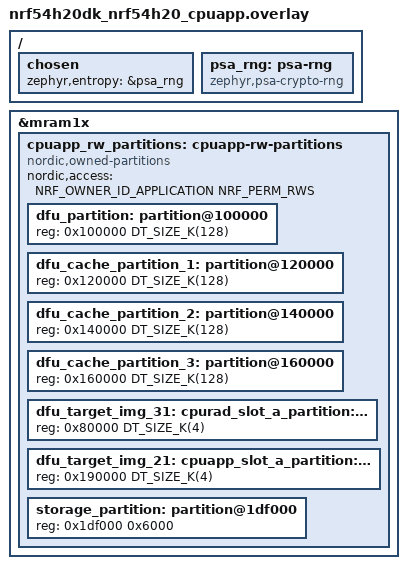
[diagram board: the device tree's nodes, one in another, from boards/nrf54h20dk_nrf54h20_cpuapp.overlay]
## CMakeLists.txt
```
#
# Copyright (c) 2024 Nordic Semiconductor
#
# SPDX-License-Identifier: LicenseRef-Nordic-5-Clause
#

cmake_minimum_required(VERSION 3.20.0)

find_package(Zephyr REQUIRED HINTS $ENV{ZEPHYR_BASE})
project(dfu_target_suit_test)
include(${ZEPHYR_NRF_MODULE_DIR}/tests/subsys/suit/cmake/test_template.cmake)

FILE(GLOB app_sources src/*.c)
target_sources(app PRIVATE ${app_sources})

target_include_directories(app
  PRIVATE
  ${ZEPHYR_NRF_MODULE_DIR}/subsys/dfu/include
  ${ZEPHYR_NRF_MODULE_DIR}/subsys/suit/ipuc/include
  ${ZEPHYR_NRF_MODULE_DIR}/subsys/suit/memory_layout/include
  "src"
  )

zephyr_compile_definitions(CONFIG_SOC_NRF54H20_CPUAPP)
```

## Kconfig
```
#
# Copyright (c) 2024 Nordic Semiconductor ASA
#
# SPDX-License-Identifier: LicenseRef-Nordic-5-Clause
#

menuconfig TESTS_SUIT_DFU_TARGET_SUIT_CACHE_PROCESSING
	bool "Run tests for processing of SUIT cache partition by the SUIT DFU target"
	imply DFU_TARGET_SUIT_CACHE_PROCESSING

menuconfig TESTS_SUIT_DFU_TARGET_SUIT_SINGLE_PARTITION
	bool "Run tests for processing of the dfu_partition only by the DFU target"

menuconfig TESTS_SUIT_DFU_TARGET_SUIT_CACHE_IPUC_PROCESSING
	bool "Run tests for processing of SUIT cache IPUC-based partition by the SUIT DFU target"
	imply DFU_TARGET_SUIT_CACHE_PROCESSING

config SUIT_CACHE_SDFW_IPUC_ID
	default 10
	depends on TESTS_SUIT_DFU_TARGET_SUIT_CACHE_IPUC_PROCESSING

source "Kconfig.zephyr"
```

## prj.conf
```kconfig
#
# Copyright (c) 2024 Nordic Semiconductor ASA
#
# SPDX-License-Identifier: LicenseRef-Nordic-5-Clause
#
CONFIG_ZTEST=y

# Enable suit
CONFIG_SUIT=y
CONFIG_SUIT_DFU=y

# Enable dfu_target
CONFIG_DFU_TARGET=y
CONFIG_DFU_TARGET_SUIT=y

# Initialize SUIT DFU by dfu_target since it is the only
# one SUIT DFU implementation in use
CONFIG_DFU_TARGET_SUIT_INITIALIZE_SUIT=y

# Choose SUIT platform APP
CONFIG_SUIT_PLATFORM_VARIANT_APP=y
```

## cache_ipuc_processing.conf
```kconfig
#
# Copyright (c) 2025 Nordic Semiconductor ASA
#
# SPDX-License-Identifier: LicenseRef-Nordic-5-Clause
#

CONFIG_TESTS_SUIT_DFU_TARGET_SUIT_CACHE_IPUC_PROCESSING=y
CONFIG_SUIT_DFU_CANDIDATE_PROCESSING_PUSH_TO_CACHE=y

CONFIG_FLASH_IPUC=y
CONFIG_FLASH_IPUC_COUNT=5
CONFIG_SUIT_IPUC=y
CONFIG_SUIT_CACHE_SDFW_IPUC=y
CONFIG_SUIT_CACHE_APP_IPUC=y
```

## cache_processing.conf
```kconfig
#
# Copyright (c) 2024 Nordic Semiconductor ASA
#
# SPDX-License-Identifier: LicenseRef-Nordic-5-Clause
#

CONFIG_TESTS_SUIT_DFU_TARGET_SUIT_CACHE_PROCESSING=y
CONFIG_SUIT_DFU_CANDIDATE_PROCESSING_PUSH_TO_CACHE=y
```

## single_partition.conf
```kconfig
#
# Copyright (c) 2024 Nordic Semiconductor ASA
#
# SPDX-License-Identifier: LicenseRef-Nordic-5-Clause
#

CONFIG_TESTS_SUIT_DFU_TARGET_SUIT_SINGLE_PARTITION=y
CONFIG_SUIT_DFU_CANDIDATE_PROCESSING_MINIMAL=y
```

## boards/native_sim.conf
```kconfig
#
# Copyright (c) 2024 Nordic Semiconductor ASA
#
# SPDX-License-Identifier: LicenseRef-Nordic-5-Clause
#

CONFIG_ZCBOR=y
CONFIG_ZCBOR_CANONICAL=y
CONFIG_FLASH_SIMULATOR=y
CONFIG_FLASH_SIMULATOR_DOUBLE_WRITES=y
CONFIG_FLASH=y
```

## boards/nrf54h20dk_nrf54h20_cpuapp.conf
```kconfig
#
# Copyright (c) 2024 Nordic Semiconductor ASA
#
# SPDX-License-Identifier: LicenseRef-Nordic-5-Clause
#

# Enable logging
CONFIG_LOG=y
CONFIG_LOG_BACKEND_UART=y
CONFIG_LOG_MODE_DEFERRED=y

# Disable SUIT SSF service and use mocks instead
CONFIG_SSF_SUIT_SERVICE_ENABLED=n
```

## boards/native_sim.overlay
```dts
/*
 * Copyright (c) 2024 Nordic Semiconductor ASA
 *
 * SPDX-License-Identifier: LicenseRef-Nordic-5-Clause
 */

&flash0 {
	partitions {
		compatible = "fixed-partitions";
		#address-cells = < 0x1 >;
		#size-cells = < 0x1 >;

		dfu_partition: partition@100000 {
			reg = < 0x100000 DT_SIZE_K(128) >;
		};

		dfu_cache_partition_1: partition@120000 {
			reg = <0x120000 DT_SIZE_K(128)>;
		};

		dfu_cache_partition_2: partition@140000 {
			reg = <0x140000 DT_SIZE_K(128)>;
		};

		dfu_cache_partition_3: partition@160000 {
			reg = <0x160000 DT_SIZE_K(128)>;
		};

		dfu_target_img_31: cpurad_slot_a_partition: partition@80000 {
			reg = <0x80000 DT_SIZE_K(4)>;
		};

		dfu_target_img_21: cpuapp_slot_a_partition: partition@190000 {
			reg = <0x190000 DT_SIZE_K(4)>;
		};
	};
};

/ {
	sram0: memory@20000000 {
		compatible = "mmio-sram";
		reg = <0x20000000 DT_SIZE_K(256)>;
	};
};
```

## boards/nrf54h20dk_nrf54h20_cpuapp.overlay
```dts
/*
 * Copyright (c) 2024 Nordic Semiconductor ASA
 *
 * SPDX-License-Identifier: LicenseRef-Nordic-5-Clause
 */

/ {
	chosen {
		zephyr,entropy = &psa_rng;
	};

	psa_rng: psa-rng {
		compatible = "zephyr,psa-crypto-rng";
		status = "okay";
	};
};

/* Split DFU partition into a smaller one and DFU caches. */
/delete-node/ &dfu_partition;
/delete-node/ &storage_partition;

&mram1x {
	cpuapp_rw_partitions: cpuapp-rw-partitions {
		compatible = "nordic,owned-partitions", "fixed-partitions";
		status = "okay";
		nordic,access = <NRF_OWNER_ID_APPLICATION NRF_PERM_RWS>;
		#address-cells = < 0x1 >;
		#size-cells = < 0x1 >;

		dfu_partition: partition@100000 {
			reg = < 0x100000 DT_SIZE_K(128) >;
		};

		dfu_cache_partition_1: partition@120000 {
			reg = <0x120000 DT_SIZE_K(128)>;
		};

		dfu_cache_partition_2: partition@140000 {
			reg = <0x140000 DT_SIZE_K(128)>;
		};

		dfu_cache_partition_3: partition@160000 {
			reg = <0x160000 DT_SIZE_K(128)>;
		};

		dfu_target_img_31: cpurad_slot_a_partition: partition@80000 {
			reg = <0x80000 DT_SIZE_K(4)>;
		};

		dfu_target_img_21: cpuapp_slot_a_partition: partition@190000 {
			reg = <0x190000 DT_SIZE_K(4)>;
		};

		storage_partition: partition@1df000 {
			reg = < 0x1df000 0x6000 >;
		};
	};
};
```

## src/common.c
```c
/*
 * Copyright (c) 2024 Nordic Semiconductor ASA
 *
 * SPDX-License-Identifier: LicenseRef-Nordic-5-Clause
 */

#include "common.h"

/* Mocks - ssf services have to be mocked, as real communication with secure domain
 * cannot take place in these tests because native_sim target does not have the secure domain
 * to communicate with, and nRF54H should not reset the device after calling
 * the dfu_target_suit_schedule_update function.
 */
DEFINE_FFF_GLOBALS;

DEFINE_FAKE_VALUE_FUNC(int, suit_trigger_update, suit_plat_mreg_t *, size_t);

void reset_fakes(void)
{
	RESET_FAKE(suit_trigger_update);
}

bool is_partition_empty(void *address, size_t size)
{
	uint8_t *partition_address = (uint8_t *)address;
	bool partition_empty = true;

	for (size_t i = 0; i < size; i++) {
		if (partition_address[i] != 0xFF) {
			partition_empty = false;
			break;
		}
	}
	return partition_empty;
}
```

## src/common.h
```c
/*
 * Copyright (c) 2024 Nordic Semiconductor ASA
 *
 * SPDX-License-Identifier: LicenseRef-Nordic-5-Clause
 */

#ifndef DFU_TARGET_SUIT_TEST_COMMON_H__
#define DFU_TARGET_SUIT_TEST_COMMON_H__

#include <stdint.h>
#include <stddef.h>

#include <zephyr/ztest.h>
#include <zephyr/devicetree.h>
#include <zephyr/fff.h>

#include <sdfw/sdfw_services/suit_service.h>
#include <suit_plat_mem_util.h>

/**
 * @brief Reset all mocked functions.
 *
 */
void reset_fakes(void);

/**
 * @brief Check whether the partition is empty.
 *
 * @param address Partition address to check.
 * @param size Partition size.
 *
 * @retval true If the partition is empty.
 * @retval false If the partition is not empty.
 */
bool is_partition_empty(void *address, size_t size);

DECLARE_FAKE_VALUE_FUNC(int, suit_trigger_update, suit_plat_mreg_t *, size_t);

#endif /* DFU_TARGET_SUIT_TEST_COMMON_H__ */
```

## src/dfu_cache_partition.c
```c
/*
 * Copyright (c) 2024 Nordic Semiconductor ASA
 *
 * SPDX-License-Identifier: LicenseRef-Nordic-5-Clause
 */

#include <stdint.h>
#include <stddef.h>

uint8_t dfu_cache_partition[] = {
	0xBF, 0x69, 0x23, 0x66, 0x69, 0x6C, 0x65, 0x2E, 0x62, 0x69, 0x6E, 0x5A, 0x00, 0x00, 0x01,
	0x00, 0xC7, 0x9C, 0xAB, 0x9D, 0xE8, 0x33, 0x7F, 0x30, 0x14, 0xEB, 0xAC, 0x02, 0xAF, 0x26,
	0x01, 0x5E, 0x80, 0x6D, 0x88, 0xA1, 0xDB, 0x11, 0xA7, 0x31, 0xDF, 0xA6, 0xEC, 0xCB, 0x9B,
	0x48, 0x0D, 0xC8, 0x34, 0x40, 0x6D, 0x30, 0x86, 0x7D, 0xE8, 0x1B, 0xEC, 0x3C, 0xF5, 0x40,
	0xD0, 0x48, 0x18, 0x82, 0x11, 0x9D, 0x7C, 0x3F, 0x6C, 0xE5, 0x8F, 0xF1, 0xD3, 0x5D, 0xE1,
	0x51, 0xF7, 0x6A, 0x0F, 0xAF, 0x0B, 0xBD, 0x4C, 0x5F, 0xA5, 0x34, 0x1A, 0x66, 0xDB, 0x22,
	0xEC, 0x63, 0xED, 0x4B, 0xAB, 0xC7, 0xC8, 0xF7, 0x59, 0xD8, 0xD6, 0x9E, 0xEC, 0x71, 0x1B,
	0x24, 0x20, 0xB9, 0xAE, 0xE1, 0x3B, 0xFC, 0xAE, 0xB8, 0x77, 0xAC, 0xA4, 0x57, 0x34, 0x97,
	0x84, 0x4F, 0x58, 0xD5, 0x68, 0x08, 0x6F, 0xE3, 0x9C, 0x7E, 0x1B, 0xD7, 0x38, 0x22, 0x98,
	0x48, 0xF8, 0x7A, 0x67, 0xB2, 0xD9, 0xAC, 0xC5, 0x34, 0xC1, 0x27, 0x82, 0x8E, 0x42, 0x79,
	0x84, 0x21, 0x37, 0x4C, 0x41, 0x4A, 0x0F, 0xE2, 0x7F, 0xA0, 0x6A, 0x19, 0x13, 0x3D, 0x52,
	0x22, 0x7F, 0xD6, 0x2F, 0x71, 0x12, 0x76, 0xAB, 0x25, 0x9C, 0xFC, 0x67, 0x08, 0x03, 0x7C,
	0xDB, 0x18, 0xE6, 0x45, 0xF8, 0x99, 0xC2, 0x9E, 0x2C, 0xE3, 0x9B, 0x25, 0xA9, 0x7B, 0x09,
	0xFF, 0x00, 0x57, 0x26, 0x08, 0x0A, 0x11, 0x42, 0xCF, 0x82, 0xA2, 0x6B, 0x2A, 0x99, 0xF9,
	0x71, 0x9D, 0x14, 0x19, 0x5C, 0x5C, 0x78, 0x31, 0x60, 0x42, 0x4A, 0x18, 0x1F, 0xEC, 0x78,
	0x6A, 0x9A, 0x7C, 0x4F, 0xCF, 0xE8, 0x5A, 0x29, 0x65, 0xCD, 0x01, 0x3B, 0x6D, 0x53, 0xBB,
	0xC6, 0xDB, 0xDA, 0xD5, 0x8F, 0xF7, 0xF4, 0xD9, 0xB9, 0x0A, 0x03, 0x4B, 0xFF, 0x33, 0xAB,
	0x3B, 0xC5, 0xAF, 0xD0, 0xB8, 0x2C, 0x0F, 0x6A, 0xA9, 0x11, 0xB0, 0xE8, 0x57, 0x8C, 0x92,
	0x53, 0x81, 0xFF};

const size_t dfu_cache_partition_len = sizeof(dfu_cache_partition);
```

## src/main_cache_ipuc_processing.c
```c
/*
 * Copyright (c) 2025 Nordic Semiconductor ASA
 *
 * SPDX-License-Identifier: LicenseRef-Nordic-5-Clause
 */

#ifdef CONFIG_TESTS_SUIT_DFU_TARGET_SUIT_CACHE_IPUC_PROCESSING

#include <dfu/dfu_target.h>
#include <dfu/dfu_target_suit.h>
#include <suit_ipuc.h>
#include <suit_dfu_cache_rw.h>
#include "common.h"

/* The SUIT envelopes are defined inside the respective manfest_*.c files. */
extern uint8_t manifest[];
extern const size_t manifest_len;
extern uint8_t dfu_cache_partition[];
extern const size_t dfu_cache_partition_len;
extern uint8_t manifest_with_payload[];
extern const size_t manifest_with_payload_len;

#define FLASH_WRITE_BLOCK_SIZE DT_PROP(DT_CHOSEN(zephyr_flash), write_block_size)

#define TEST_IMAGE_SIZE		1024
#define TEST_IMAGE_ENVELOPE_NUM 0
#define TEST_IMAGE_CACHE_1_NUM	2
#define TEST_IMAGE_CACHE_2_NUM	3
#define TEST_IMAGE_CACHE_3_NUM	4

#define DFU_PARTITION_LABEL   dfu_partition
#define DFU_PARTITION_OFFSET  FIXED_PARTITION_OFFSET(DFU_PARTITION_LABEL)
#define DFU_PARTITION_ADDRESS suit_plat_mem_nvm_ptr_get(DFU_PARTITION_OFFSET)
#define DFU_PARTITION_SIZE    FIXED_PARTITION_SIZE(DFU_PARTITION_LABEL)
#define DFU_PARTITION_DEVICE  FIXED_PARTITION_DEVICE(DFU_PARTITION_LABEL)

#define CACHE_PARTITION_LABEL(N)   dfu_cache_partition_##N
#define CACHE_PARTITION_OFFSET(N)  FIXED_PARTITION_OFFSET(CACHE_PARTITION_LABEL(N))
#define CACHE_PARTITION_ADDRESS(N) suit_plat_mem_nvm_ptr_get(CACHE_PARTITION_OFFSET(N))
#define CACHE_PARTITION_SIZE(N)	   FIXED_PARTITION_SIZE(CACHE_PARTITION_LABEL(N))
#define CACHE_PARTITION_DEVICE(N)  FIXED_PARTITION_DEVICE(CACHE_PARTITION_LABEL(N))

#define IPUC_PARTITION_APP_ADDRESS                                                                 \
	suit_plat_mem_nvm_ptr_get(FIXED_PARTITION_OFFSET(cpuapp_slot_a_partition))
#define IPUC_PARTITION_RAD_ADDRESS                                                                 \
	suit_plat_mem_nvm_ptr_get(FIXED_PARTITION_OFFSET(cpurad_slot_a_partition))

static uint8_t dfu_target_buffer[TEST_IMAGE_SIZE];

FAKE_VALUE_FUNC(int, suit_ipuc_get_count, size_t *);
FAKE_VALUE_FUNC(int, suit_ipuc_get_info, size_t, struct zcbor_string *, suit_manifest_role_t *);
FAKE_VALUE_FUNC(int, suit_ipuc_write_setup, struct zcbor_string *, struct zcbor_string *,
		struct zcbor_string *);
FAKE_VALUE_FUNC(int, suit_ipuc_write, struct zcbor_string *, size_t, uintptr_t, size_t, bool);

static inline void mock_suit_ipuc_reset(void)
{
	RESET_FAKE(suit_ipuc_get_count);
	RESET_FAKE(suit_ipuc_get_info);
	RESET_FAKE(suit_ipuc_write_setup);
	RESET_FAKE(suit_ipuc_write);
}

/* clang-format off */
#ifndef CONFIG_SOC_SERIES_NRF54HX
static const uint8_t component_rad_0x80000_0x1000[] = {
	0x84, /* array(4) */
		0x44, /* bstr(4) */
			0x63, /* text(3) */
				'M', 'E', 'M',
		0x41, /* bstr(1) */
			0x03, /* Radio domain executable */
		0x45, /* bstr(5) */
			0x1a, /* uint32 */
				0x00, 0x08, 0x00, 0x00,
		0x43, /* bstr(3) */
			0x19, /* uint16 */
				0x10, 0x00,
};
static const uint8_t component_app_0x190000_0x1000[] = {
	0x84, /* array(4) */
		0x44, /* bstr(4) */
			0x63, /* text(3) */
				'M', 'E', 'M',
		0x41, /* bstr(1) */
			0x02, /* Application domain executable */
		0x45, /* bstr(5) */
			0x1a, /* uint32 */
				0x00, 0x19, 0x00, 0x00,
		0x43, /* bstr(3) */
			0x19, /* uint16 */
				0x10, 0x00,
};
#else /* CONFIG_SOC_SERIES_NRF54HX */
static const uint8_t component_rad_0x80000_0x1000[] = {
	0x84, /* array(4) */
		0x44, /* bstr(4) */
			0x63, /* text(3) */
				'M', 'E', 'M',
		0x41, /* bstr(1) */
			0x03, /* Radio domain executable */
		0x45, /* bstr(5) */
			0x1a, /* uint32 */
				0x0e, 0x08, 0x00, 0x00,
		0x43, /* bstr(3) */
			0x19, /* uint16 */
				0x10, 0x00,
};
static const uint8_t component_app_0x190000_0x1000[] = {
	0x84, /* array(4) */
		0x44, /* bstr(4) */
			0x63, /* text(3) */
				'M', 'E', 'M',
		0x41, /* bstr(1) */
			0x02, /* Application domain executable */
		0x45, /* bstr(5) */
			0x1a, /* uint32 */
				0x0e, 0x19, 0x00, 0x00,
		0x43, /* bstr(3) */
			0x19, /* uint16 */
				0x10, 0x00,
};
#endif /* CONFIG_SOC_SERIES_NRF54HX */
/* clang-format on */

static suit_plat_err_t suit_ipuc_get_count_fake_func(size_t *count)
{
	zassert_not_null(count, "Caller must provide non-Null pointer");

	*count = 2;

	return SUIT_PLAT_SUCCESS;
}

static suit_plat_err_t suit_ipuc_get_info_fake_func(size_t idx, struct zcbor_string *component_id,
						    suit_manifest_role_t *role)
{
	zassert_not_null(component_id, "Caller must provide non-Null pointer to read component_id");
	zassert_not_null(role, "Caller must provide non-Null pointer to read role");
	zassert_true(idx < 2, "Unexpected idx value");

	if (idx == 0) {
		component_id->value = component_rad_0x80000_0x1000;
		component_id->len = sizeof(component_rad_0x80000_0x1000);
		*role = SUIT_MANIFEST_RAD_LOCAL_1;
	} else if (idx == 1) {
		component_id->value = component_app_0x190000_0x1000;
		component_id->len = sizeof(component_app_0x190000_0x1000);
		*role = SUIT_MANIFEST_APP_LOCAL_1;
	}

	return SUIT_PLAT_SUCCESS;
}

static void emulte_unaligned_write(size_t offset, uint8_t *buf, size_t len)
{
	uint8_t flash_write_buf[FLASH_WRITE_BLOCK_SIZE] = {0};
	size_t aligned_offset = 0;
	size_t bytes_cached = 0;
	size_t bytes_consumed = 0;

	aligned_offset = (offset / FLASH_WRITE_BLOCK_SIZE) * FLASH_WRITE_BLOCK_SIZE;
	if (aligned_offset != offset) {
		bytes_cached = offset - aligned_offset;
		bytes_consumed = MIN(FLASH_WRITE_BLOCK_SIZE - bytes_cached, len);

		zassert_equal(flash_read(SUIT_PLAT_INTERNAL_NVM_DEV, aligned_offset,
					 flash_write_buf, bytes_cached),
			      0, "Unable to cache data");
		memcpy(&flash_write_buf[bytes_cached], buf, bytes_consumed);
		zassert_equal(flash_write(SUIT_PLAT_INTERNAL_NVM_DEV, aligned_offset,
					  flash_write_buf, sizeof(flash_write_buf)),
			      0, "Unable to modify NVM to match requested changes");

		len -= bytes_consumed;
		buf += bytes_consumed;
		aligned_offset += sizeof(flash_write_buf);
	}

	if (len / FLASH_WRITE_BLOCK_SIZE > 0) {
		bytes_consumed = (len / FLASH_WRITE_BLOCK_SIZE) * FLASH_WRITE_BLOCK_SIZE;
		zassert_equal(flash_write(SUIT_PLAT_INTERNAL_NVM_DEV, aligned_offset, buf,
					  bytes_consumed),
			      0, "Unable to modify NVM to match requested changes");

		len -= bytes_consumed;
		buf += bytes_consumed;
		aligned_offset += bytes_consumed;
	}

	if (len > 0) {
		memset(flash_write_buf, 0xFF, sizeof(flash_write_buf));
		memcpy(flash_write_buf, buf, len);
		zassert_equal(flash_write(SUIT_PLAT_INTERNAL_NVM_DEV, aligned_offset,
					  flash_write_buf, sizeof(flash_write_buf)),
			      0, "Unable to modify NVM to match requested changes");
	}
}

static suit_plat_err_t suit_ipuc_write_fake_func(struct zcbor_string *component_id, size_t offset,
						 uintptr_t buffer, size_t chunk_size,
						 bool last_chunk)
{
	zassert_not_null(component_id, "Caller must provide non-Null pointer to read component_id");
	zassert_equal(component_id->len, sizeof(component_app_0x190000_0x1000),
		      "Invalid component ID length passed");
	if (memcmp(component_id->value, component_app_0x190000_0x1000, component_id->len) == 0) {
		emulte_unaligned_write(0x190000 + offset, (uint8_t *)buffer, chunk_size);
	} else if (memcmp(component_id->value, component_rad_0x80000_0x1000, component_id->len) ==
		   0) {
		emulte_unaligned_write(0x80000 + offset, (uint8_t *)buffer, chunk_size);
	} else {
		zassert_true(false, "Invalid component ID value passed");
	}

	return SUIT_PLAT_SUCCESS;
}

static suit_plat_err_t suit_ipuc_write_setup_fake_func(struct zcbor_string *component_id,
						       struct zcbor_string *encryption_info,
						       struct zcbor_string *compression_info)
{
	zassert_is_null(encryption_info, "Decryption info unsupported by cache IPUCs");
	zassert_is_null(compression_info, "Decompression info unsupported by cache IPUCs");
	zassert_not_null(component_id, "Caller must provide non-Null pointer to read component_id");
	zassert_equal(component_id->len, sizeof(component_app_0x190000_0x1000),
		      "Invalid component ID length passed");
	if (memcmp(component_id->value, component_app_0x190000_0x1000, component_id->len) == 0) {
		zassert_equal(flash_erase(SUIT_PLAT_INTERNAL_NVM_DEV, 0x190000, 0x1000), 0,
			      "Unable to modify NVM to match requested changes");
	} else if (memcmp(component_id->value, component_rad_0x80000_0x1000, component_id->len) ==
		   0) {
		zassert_equal(flash_erase(SUIT_PLAT_INTERNAL_NVM_DEV, 0x80000, 0x1000), 0,
			      "Unable to modify NVM to match requested changes");
	} else {
		zassert_true(false, "Invalid component ID value passed");
	}

	return SUIT_PLAT_SUCCESS;
}

static void setup_test(void *f)
{
	(void)f;

	reset_fakes();
	mock_suit_ipuc_reset();

	suit_ipuc_get_count_fake.custom_fake = suit_ipuc_get_count_fake_func;
	suit_ipuc_get_info_fake.custom_fake = suit_ipuc_get_info_fake_func;
	suit_ipuc_write_fake.custom_fake = suit_ipuc_write_fake_func;
	suit_ipuc_write_setup_fake.custom_fake = suit_ipuc_write_setup_fake_func;

	/* Reinitialize DFU cache, so the values returned through fakes are applied. */
	suit_dfu_cache_rw_init();
}

ZTEST(dfu_target_suit, test_image_init)
{
	int rc;

	rc = dfu_target_suit_reset();
	zassert_equal(rc, 0, "Unexpected failure: %d", rc);

	zassert_equal(is_partition_empty(DFU_PARTITION_ADDRESS, DFU_PARTITION_SIZE), true,
		      "Partition should be empty after calling dfu_target_reset");
	zassert_equal(is_partition_empty(CACHE_PARTITION_ADDRESS(1), CACHE_PARTITION_SIZE(1)), true,
		      "Partition should be empty after calling dfu_target_reset");
	zassert_equal(is_partition_empty(CACHE_PARTITION_ADDRESS(2), CACHE_PARTITION_SIZE(2)), true,
		      "Partition should be empty after calling dfu_target_reset");
	zassert_equal(is_partition_empty(CACHE_PARTITION_ADDRESS(3), CACHE_PARTITION_SIZE(3)), true,
		      "Partition should be empty after calling dfu_target_reset");

	rc = dfu_target_init(DFU_TARGET_IMAGE_TYPE_SUIT, TEST_IMAGE_ENVELOPE_NUM, TEST_IMAGE_SIZE,
			     NULL);
	zassert_equal(rc, -ENODEV,
		      "dfu_target should fail because the buffer has not been initialized. %d", rc);

	rc = dfu_target_suit_set_buf(dfu_target_buffer, sizeof(dfu_target_buffer));
	zassert_equal(rc, 0, "dfu_target should initialize the data buffer %d", rc);

	rc = dfu_target_init(DFU_TARGET_IMAGE_TYPE_SUIT, TEST_IMAGE_ENVELOPE_NUM,
			     TEST_IMAGE_SIZE * 1000, NULL);
	zassert_equal(rc, -EFBIG, "dfu_target should not allow too big files. %d", rc);

	rc = dfu_target_init(DFU_TARGET_IMAGE_TYPE_SUIT, TEST_IMAGE_ENVELOPE_NUM, TEST_IMAGE_SIZE,
			     NULL);
	zassert_equal(rc, 0, "Unexpected failure: %d", rc);

	rc = dfu_target_init(DFU_TARGET_IMAGE_TYPE_SUIT, TEST_IMAGE_ENVELOPE_NUM, TEST_IMAGE_SIZE,
			     NULL);
	zassert_equal(rc, -EBUSY,
		      "dfu_target should not initialize the same image twice until the stream is "
		      "not ended or reset. %d",
		      rc);

	rc = dfu_target_suit_reset();
	zassert_equal(rc, 0, "Unexpected failure: %d", rc);

	rc = dfu_target_init(DFU_TARGET_IMAGE_TYPE_SUIT, TEST_IMAGE_CACHE_1_NUM, TEST_IMAGE_SIZE,
			     NULL);
	zassert_equal(rc, 0, "Unexpected failure: %d", rc);

	rc = dfu_target_suit_reset();
	zassert_equal(rc, 0, "Unexpected failure: %d", rc);

	rc = dfu_target_init(DFU_TARGET_IMAGE_TYPE_SUIT, CONFIG_SUIT_CACHE_SDFW_IPUC_ID + 1,
			     TEST_IMAGE_SIZE, NULL);
	zassert_equal(rc, 0, "Unexpected failure: %d", rc);

	rc = dfu_target_suit_reset();
	zassert_equal(rc, 0, "Unexpected failure: %d", rc);

	rc = dfu_target_init(DFU_TARGET_IMAGE_TYPE_SUIT, CONFIG_SUIT_CACHE_APP_IPUC_ID + 1,
			     TEST_IMAGE_SIZE, NULL);
	zassert_equal(rc, 0, "Unexpected failure: %d", rc);

	rc = dfu_target_suit_reset();
	zassert_equal(rc, 0, "Unexpected failure: %d", rc);

	rc = dfu_target_init(DFU_TARGET_IMAGE_TYPE_SUIT, 21, TEST_IMAGE_SIZE, NULL);
	zassert_equal(rc, 0, "Unexpected failure: %d", rc);

	rc = dfu_target_suit_reset();
	zassert_equal(rc, 0, "Unexpected failure: %d", rc);

	rc = dfu_target_init(DFU_TARGET_IMAGE_TYPE_SUIT, 31, TEST_IMAGE_SIZE, NULL);
	zassert_equal(rc, 0, "Unexpected failure: %d", rc);

	rc = dfu_target_suit_reset();
	zassert_equal(rc, 0, "Unexpected failure: %d", rc);
}

ZTEST(dfu_target_suit, test_image_upload)
{
	int rc;
	size_t offset = 0;

	rc = dfu_target_suit_reset();
	zassert_equal(rc, 0, "Unexpected failure: %d", rc);

	rc = dfu_target_suit_write(manifest, TEST_IMAGE_SIZE);
	zassert_equal(rc, -EFAULT, "Unexpected failure: %d", rc);

	rc = dfu_target_suit_offset_get(&offset);
	zassert_equal(rc, 0, "Unexpected failure: %d", rc);
	zassert_equal(offset, 0, "DFU target offset should be equal to 0");

	rc = dfu_target_suit_set_buf(dfu_target_buffer, sizeof(dfu_target_buffer));
	zassert_equal(rc, 0, "Unexpected failure: %d", rc);

	rc = dfu_target_init(DFU_TARGET_IMAGE_TYPE_SUIT, TEST_IMAGE_ENVELOPE_NUM, manifest_len,
			     NULL);
	zassert_equal(rc, 0, "Unexpected failure: %d", rc);

	rc = dfu_target_suit_write(manifest, manifest_len);
	zassert_equal(rc, 0, "Unexpected failure: %d", rc);

	rc = dfu_target_suit_offset_get(&offset);
	zassert_equal(rc, 0, "DFU target offset get should pass for image 0 %d", rc);
	zassert_equal(offset, manifest_len, "DFU target offset should be equal to image size");

	rc = dfu_target_done(true);
	zassert_equal(rc, 0, "Unexpected failure: %d", rc);

	rc = dfu_target_init(DFU_TARGET_IMAGE_TYPE_SUIT, 21, TEST_IMAGE_SIZE, NULL);
	zassert_equal(rc, 0, "Unexpected failure: %d", rc);

	rc = dfu_target_suit_write(dfu_cache_partition, dfu_cache_partition_len);
	zassert_equal(rc, 0, "Unexpected failure: %d", rc);

	rc = dfu_target_suit_offset_get(&offset);
	zassert_equal(rc, 0, "DFU target offset get should pass for image 0 %d", rc);
	zassert_equal(offset, dfu_cache_partition_len,
		      "DFU target offset should be equal to image size");

	rc = dfu_target_done(true);
	zassert_equal(rc, 0, "Unexpected failure: %d", rc);

	rc = dfu_target_init(DFU_TARGET_IMAGE_TYPE_SUIT, 31, TEST_IMAGE_SIZE, NULL);
	zassert_equal(rc, 0, "Unexpected failure: %d", rc);

	rc = dfu_target_suit_write(dfu_cache_partition, dfu_cache_partition_len);
	zassert_equal(rc, 0, "Unexpected failure: %d", rc);

	rc = dfu_target_suit_offset_get(&offset);
	zassert_equal(rc, 0, "DFU target offset get should pass for image 0 %d", rc);
	zassert_equal(offset, dfu_cache_partition_len,
		      "DFU target offset should be equal to image size");

	rc = dfu_target_done(true);
	zassert_equal(rc, 0, "Unexpected failure: %d", rc);

	rc = dfu_target_suit_schedule_update(0);
	zassert_equal(rc, 0, "Unexpected failure: %d", rc);

	dfu_target_suit_reboot();
	zassert_equal(suit_trigger_update_fake.call_count, 1,
		      "Incorrect number of suit_dfu_update_start() calls");

	rc = memcmp((uint8_t *)DFU_PARTITION_ADDRESS, manifest, manifest_len);
	zassert_equal(rc, 0, "DFU partition content does not match the manifest %d", rc);

	rc = memcmp((uint8_t *)IPUC_PARTITION_APP_ADDRESS, dfu_cache_partition,
		    dfu_cache_partition_len);
	zassert_equal(rc, 0, "DFU cache partition content does not match the file content %d", rc);

	rc = memcmp((uint8_t *)IPUC_PARTITION_RAD_ADDRESS, dfu_cache_partition,
		    dfu_cache_partition_len);
	zassert_equal(rc, 0, "DFU cache partition content does not match the file content %d", rc);

	rc = dfu_target_suit_reset();
	zassert_equal(rc, 0, "Unexpected failure: %d", rc);

	rc = memcmp((uint8_t *)IPUC_PARTITION_APP_ADDRESS, dfu_cache_partition,
		    dfu_cache_partition_len);
	zassert_equal(rc, 0, "DFU cache partition content does not match the file content %d", rc);

	rc = memcmp((uint8_t *)IPUC_PARTITION_RAD_ADDRESS, dfu_cache_partition,
		    dfu_cache_partition_len);
	zassert_equal(rc, 0, "DFU cache partition content does not match the file content %d", rc);
}

ZTEST(dfu_target_suit, test_image_multi_cache_upload)
{
	int rc;
	size_t offset = 0;

	RESET_FAKE(suit_trigger_update);

	rc = dfu_target_suit_reset();
	zassert_equal(rc, 0, "Unexpected failure: %d", rc);

	rc = dfu_target_suit_set_buf(dfu_target_buffer, sizeof(dfu_target_buffer));
	zassert_equal(rc, 0, "Unexpected failure: %d", rc);

	rc = dfu_target_init(DFU_TARGET_IMAGE_TYPE_SUIT, TEST_IMAGE_ENVELOPE_NUM, manifest_len,
			     NULL);
	zassert_equal(rc, 0, "Unexpected failure: %d", rc);

	rc = dfu_target_suit_write(manifest, manifest_len);
	zassert_equal(rc, 0, "Unexpected failure: %d", rc);

	rc = dfu_target_suit_offset_get(&offset);
	zassert_equal(rc, 0, "DFU target offset get should pass for image 0 %d", rc);
	zassert_equal(offset, manifest_len, "DFU target offset should be equal to image size");

	rc = dfu_target_done(true);
	zassert_equal(rc, 0, "Unexpected failure: %d", rc);

	rc = dfu_target_init(DFU_TARGET_IMAGE_TYPE_SUIT, TEST_IMAGE_CACHE_1_NUM,
			     dfu_cache_partition_len, NULL);
	zassert_equal(rc, 0, "Unexpected failure: %d", rc);

	rc = dfu_target_suit_write(dfu_cache_partition, dfu_cache_partition_len);
	zassert_equal(rc, 0, "Unexpected failure: %d", rc);

	rc = dfu_target_suit_offset_get(&offset);
	zassert_equal(rc, 0, "Unexpected failure: %d", rc);
	zassert_equal(offset, dfu_cache_partition_len,
		      "DFU target offset should be equal to image size");

	rc = dfu_target_done(true);
	zassert_equal(rc, 0, "Unexpected failure: %d", rc);

	rc = dfu_target_init(DFU_TARGET_IMAGE_TYPE_SUIT, TEST_IMAGE_CACHE_2_NUM,
			     dfu_cache_partition_len, NULL);
	zassert_equal(rc, 0, "Unexpected failure: %d", rc);

	rc = dfu_target_suit_write(dfu_cache_partition, dfu_cache_partition_len);
	zassert_equal(rc, 0, "Unexpected failure: %d", rc);

	rc = dfu_target_suit_offset_get(&offset);
	zassert_equal(rc, 0, "Unexpected failure: %d", rc);
	zassert_equal(offset, dfu_cache_partition_len,
		      "DFU target offset should be equal to image size");

	rc = dfu_target_done(true);
	zassert_equal(rc, 0, "Unexpected failure: %d", rc);

	rc = dfu_target_init(DFU_TARGET_IMAGE_TYPE_SUIT, TEST_IMAGE_CACHE_3_NUM,
			     dfu_cache_partition_len, NULL);
	zassert_equal(rc, 0, "Unexpected failure: %d", rc);

	rc = dfu_target_suit_write(dfu_cache_partition, dfu_cache_partition_len);
	zassert_equal(rc, 0, "Unexpected failure: %d", rc);

	rc = dfu_target_suit_offset_get(&offset);
	zassert_equal(rc, 0, "Unexpected failure: %d", rc);
	zassert_equal(offset, dfu_cache_partition_len,
		      "DFU target offset should be equal to image size");

	rc = dfu_target_done(true);
	zassert_equal(rc, 0, "Unexpected failure: %d", rc);

	rc = dfu_target_init(DFU_TARGET_IMAGE_TYPE_SUIT, CONFIG_SUIT_CACHE_SDFW_IPUC_ID + 1,
			     dfu_cache_partition_len, NULL);
	zassert_equal(rc, 0, "Unexpected failure: %d", rc);

	rc = dfu_target_suit_write(dfu_cache_partition, dfu_cache_partition_len);
	zassert_equal(rc, 0, "Unexpected failure: %d", rc);

	rc = dfu_target_suit_offset_get(&offset);
	zassert_equal(rc, 0, "Unexpected failure: %d", rc);
	zassert_equal(offset, dfu_cache_partition_len,
		      "DFU target offset should be equal to image size");

	rc = dfu_target_done(true);
	zassert_equal(rc, 0, "Unexpected failure: %d", rc);

	rc = dfu_target_init(DFU_TARGET_IMAGE_TYPE_SUIT, CONFIG_SUIT_CACHE_APP_IPUC_ID + 1,
			     dfu_cache_partition_len, NULL);
	zassert_equal(rc, 0, "Unexpected failure: %d", rc);

	rc = dfu_target_suit_write(dfu_cache_partition, dfu_cache_partition_len);
	zassert_equal(rc, 0, "Unexpected failure: %d", rc);

	rc = dfu_target_suit_offset_get(&offset);
	zassert_equal(rc, 0, "Unexpected failure: %d", rc);
	zassert_equal(offset, dfu_cache_partition_len,
		      "DFU target offset should be equal to image size");

	rc = dfu_target_done(true);
	zassert_equal(rc, 0, "Unexpected failure: %d", rc);

	rc = dfu_target_suit_schedule_update(0);
	zassert_equal(rc, 0, "Unexpected failure: %d", rc);

	dfu_target_suit_reboot();
	zassert_equal(suit_trigger_update_fake.call_count, 1,
		      "Incorrect number of suit_dfu_update_start() calls");

	rc = memcmp((uint8_t *)DFU_PARTITION_ADDRESS, manifest, manifest_len);
	zassert_equal(rc, 0, "DFU partition content does not match the manifest %d", rc);

	rc = memcmp((uint8_t *)CACHE_PARTITION_ADDRESS(1), dfu_cache_partition,
		    dfu_cache_partition_len);
	zassert_equal(rc, 0, "DFU cache partition content does not match the file content %d", rc);

	rc = memcmp((uint8_t *)CACHE_PARTITION_ADDRESS(2), dfu_cache_partition,
		    dfu_cache_partition_len);
	zassert_equal(rc, 0, "DFU cache partition content does not match the file content %d", rc);

	rc = memcmp((uint8_t *)CACHE_PARTITION_ADDRESS(3), dfu_cache_partition,
		    dfu_cache_partition_len);
	zassert_equal(rc, 0, "DFU cache partition content does not match the file content %d", rc);

	rc = dfu_target_suit_reset();
	zassert_equal(rc, 0, "Unexpected failure: %d", rc);

	zassert_equal(is_partition_empty(DFU_PARTITION_ADDRESS, DFU_PARTITION_SIZE), true,
		      "Partition should be empty after calling dfu_target_reset");
	zassert_equal(is_partition_empty(CACHE_PARTITION_ADDRESS(1), CACHE_PARTITION_SIZE(1)), true,
		      "Partition should be empty after calling dfu_target_reset");
	zassert_equal(is_partition_empty(CACHE_PARTITION_ADDRESS(2), CACHE_PARTITION_SIZE(2)), true,
		      "Partition should be empty after calling dfu_target_reset");
	zassert_equal(is_partition_empty(CACHE_PARTITION_ADDRESS(3), CACHE_PARTITION_SIZE(3)), true,
		      "Partition should be empty after calling dfu_target_reset");
}

ZTEST_SUITE(dfu_target_suit, NULL, NULL, setup_test, NULL, NULL);

#endif /* CONFIG_TESTS_SUIT_DFU_TARGET_SUIT_CACHE_IPUC_PROCESSING */
```

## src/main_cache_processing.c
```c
/*
 * Copyright (c) 2024 Nordic Semiconductor ASA
 *
 * SPDX-License-Identifier: LicenseRef-Nordic-5-Clause
 */

#ifdef CONFIG_TESTS_SUIT_DFU_TARGET_SUIT_CACHE_PROCESSING

#include <dfu/dfu_target.h>
#include <dfu/dfu_target_suit.h>

#include "common.h"

/* The SUIT envelopes are defined inside the respective manfest_*.c files. */
extern uint8_t manifest[];
extern const size_t manifest_len;
extern uint8_t dfu_cache_partition[];
extern const size_t dfu_cache_partition_len;
extern uint8_t manifest_with_payload[];
extern const size_t manifest_with_payload_len;

#define TEST_IMAGE_SIZE		1024
#define TEST_IMAGE_ENVELOPE_NUM 0
#define TEST_IMAGE_CACHE_1_NUM	2
#define TEST_IMAGE_CACHE_2_NUM	3
#define TEST_IMAGE_CACHE_3_NUM	4

#define DFU_PARTITION_LABEL   dfu_partition
#define DFU_PARTITION_OFFSET  FIXED_PARTITION_OFFSET(DFU_PARTITION_LABEL)
#define DFU_PARTITION_ADDRESS suit_plat_mem_nvm_ptr_get(DFU_PARTITION_OFFSET)
#define DFU_PARTITION_SIZE    FIXED_PARTITION_SIZE(DFU_PARTITION_LABEL)
#define DFU_PARTITION_DEVICE  FIXED_PARTITION_DEVICE(DFU_PARTITION_LABEL)

#define CACHE_PARTITION_LABEL(N)   dfu_cache_partition_##N
#define CACHE_PARTITION_OFFSET(N)  FIXED_PARTITION_OFFSET(CACHE_PARTITION_LABEL(N))
#define CACHE_PARTITION_ADDRESS(N) suit_plat_mem_nvm_ptr_get(CACHE_PARTITION_OFFSET(N))
#define CACHE_PARTITION_SIZE(N)	   FIXED_PARTITION_SIZE(CACHE_PARTITION_LABEL(N))
#define CACHE_PARTITION_DEVICE(N)  FIXED_PARTITION_DEVICE(CACHE_PARTITION_LABEL(N))

static uint8_t dfu_target_buffer[TEST_IMAGE_SIZE];

static void setup_test(void *f)
{
	(void)f;

	reset_fakes();
}

ZTEST(dfu_target_suit, test_image_init)
{
	int rc;

	rc = dfu_target_suit_reset();
	zassert_equal(rc, 0, "Unexpected failure: %d", rc);

	zassert_equal(is_partition_empty(DFU_PARTITION_ADDRESS, DFU_PARTITION_SIZE), true,
		      "Partition should be empty after calling dfu_target_reset");
	zassert_equal(is_partition_empty(CACHE_PARTITION_ADDRESS(1), CACHE_PARTITION_SIZE(1)), true,
		      "Partition should be empty after calling dfu_target_reset");
	zassert_equal(is_partition_empty(CACHE_PARTITION_ADDRESS(2), CACHE_PARTITION_SIZE(2)), true,
		      "Partition should be empty after calling dfu_target_reset");
	zassert_equal(is_partition_empty(CACHE_PARTITION_ADDRESS(3), CACHE_PARTITION_SIZE(3)), true,
		      "Partition should be empty after calling dfu_target_reset");

	rc = dfu_target_init(DFU_TARGET_IMAGE_TYPE_SUIT, TEST_IMAGE_ENVELOPE_NUM, TEST_IMAGE_SIZE,
			     NULL);
	zassert_equal(rc, -ENODEV,
		      "dfu_target should fail because the buffer has not been initialized. %d", rc);

	rc = dfu_target_suit_set_buf(dfu_target_buffer, sizeof(dfu_target_buffer));
	zassert_equal(rc, 0, "dfu_target should initialize the data buffer %d", rc);

	rc = dfu_target_init(DFU_TARGET_IMAGE_TYPE_SUIT, TEST_IMAGE_ENVELOPE_NUM,
			     TEST_IMAGE_SIZE * 1000, NULL);
	zassert_equal(rc, -EFBIG, "dfu_target should not allow too big files. %d", rc);

	rc = dfu_target_init(DFU_TARGET_IMAGE_TYPE_SUIT, TEST_IMAGE_ENVELOPE_NUM, TEST_IMAGE_SIZE,
			     NULL);
	zassert_equal(rc, 0, "Unexpected failure: %d", rc);

	rc = dfu_target_init(DFU_TARGET_IMAGE_TYPE_SUIT, TEST_IMAGE_ENVELOPE_NUM, TEST_IMAGE_SIZE,
			     NULL);
	zassert_equal(rc, -EBUSY,
		      "dfu_target should not initialize the same image twice until the stream is "
		      "not ended or reset. %d",
		      rc);

	rc = dfu_target_suit_reset();
	zassert_equal(rc, 0, "Unexpected failure: %d", rc);

	rc = dfu_target_init(DFU_TARGET_IMAGE_TYPE_SUIT, TEST_IMAGE_CACHE_1_NUM, TEST_IMAGE_SIZE,
			     NULL);
	zassert_equal(rc, 0, "Unexpected failure: %d", rc);
}

ZTEST(dfu_target_suit, test_image_upload)
{
	int rc;
	size_t offset = 0;

	rc = dfu_target_suit_reset();
	zassert_equal(rc, 0, "Unexpected failure: %d", rc);

	rc = dfu_target_suit_write(manifest, TEST_IMAGE_SIZE);
	zassert_equal(rc, -EFAULT, "Unexpected failure: %d", rc);

	rc = dfu_target_suit_offset_get(&offset);
	zassert_equal(rc, 0, "Unexpected failure: %d", rc);
	zassert_equal(offset, 0, "DFU target offset should be equal to 0");

	rc = dfu_target_suit_set_buf(dfu_target_buffer, sizeof(dfu_target_buffer));
	zassert_equal(rc, 0, "Unexpected failure: %d", rc);

	rc = dfu_target_init(DFU_TARGET_IMAGE_TYPE_SUIT, TEST_IMAGE_ENVELOPE_NUM, manifest_len,
			     NULL);
	zassert_equal(rc, 0, "Unexpected failure: %d", rc);

	rc = dfu_target_suit_write(manifest, manifest_len);
	zassert_equal(rc, 0, "Unexpected failure: %d", rc);

	rc = dfu_target_suit_offset_get(&offset);
	zassert_equal(rc, 0, "DFU target offset get should pass for image 0 %d", rc);
	zassert_equal(offset, manifest_len, "DFU target offset should be equal to image size");

	rc = dfu_target_done(true);
	zassert_equal(rc, 0, "Unexpected failure: %d", rc);

	rc = dfu_target_init(DFU_TARGET_IMAGE_TYPE_SUIT, TEST_IMAGE_CACHE_1_NUM,
			     dfu_cache_partition_len, NULL);
	zassert_equal(rc, 0, "Unexpected failure: %d", rc);

	rc = dfu_target_suit_write(dfu_cache_partition, dfu_cache_partition_len);
	zassert_equal(rc, 0, "Unexpected failure: %d", rc);

	rc = dfu_target_suit_offset_get(&offset);
	zassert_equal(rc, 0, "DFU target offset get should pass for image 0 %d", rc);
	zassert_equal(offset, dfu_cache_partition_len,
		      "DFU target offset should be equal to image size");

	rc = dfu_target_done(true);
	zassert_equal(rc, 0, "Unexpected failure: %d", rc);

	rc = dfu_target_suit_schedule_update(0);
	zassert_equal(rc, 0, "Unexpected failure: %d", rc);

	dfu_target_suit_reboot();
	zassert_equal(suit_trigger_update_fake.call_count, 1,
		      "Incorrect number of suit_dfu_update_start() calls");

	rc = memcmp((uint8_t *)DFU_PARTITION_ADDRESS, manifest, manifest_len);
	zassert_equal(rc, 0, "DFU partition content does not match the manifest %d", rc);

	rc = memcmp((uint8_t *)CACHE_PARTITION_ADDRESS(1), dfu_cache_partition,
		    dfu_cache_partition_len);
	zassert_equal(rc, 0, "DFU cache partition content does not match the file content %d", rc);

	zassert_equal(is_partition_empty(CACHE_PARTITION_ADDRESS(2), CACHE_PARTITION_SIZE(2)), true,
		      "Partition should be empty after because it was not used");
	zassert_equal(is_partition_empty(CACHE_PARTITION_ADDRESS(3), CACHE_PARTITION_SIZE(3)), true,
		      "Partition should be empty after because it was not used");

	rc = dfu_target_suit_reset();
	zassert_equal(rc, 0, "Unexpected failure: %d", rc);

	zassert_equal(is_partition_empty(DFU_PARTITION_ADDRESS, DFU_PARTITION_SIZE), true,
		      "Partition should be empty after calling dfu_target_reset");
	zassert_equal(is_partition_empty(CACHE_PARTITION_ADDRESS(1), CACHE_PARTITION_SIZE(1)), true,
		      "Partition should be empty after calling dfu_target_reset");
	zassert_equal(is_partition_empty(CACHE_PARTITION_ADDRESS(2), CACHE_PARTITION_SIZE(2)), true,
		      "Partition should be empty after calling dfu_target_reset");
	zassert_equal(is_partition_empty(CACHE_PARTITION_ADDRESS(3), CACHE_PARTITION_SIZE(3)), true,
		      "Partition should be empty after calling dfu_target_reset");
}

ZTEST(dfu_target_suit, test_image_multi_cache_upload)
{
	int rc;
	size_t offset = 0;

	RESET_FAKE(suit_trigger_update);

	rc = dfu_target_suit_reset();
	zassert_equal(rc, 0, "Unexpected failure: %d", rc);

	rc = dfu_target_suit_set_buf(dfu_target_buffer, sizeof(dfu_target_buffer));
	zassert_equal(rc, 0, "Unexpected failure: %d", rc);

	rc = dfu_target_init(DFU_TARGET_IMAGE_TYPE_SUIT, TEST_IMAGE_ENVELOPE_NUM, manifest_len,
			     NULL);
	zassert_equal(rc, 0, "Unexpected failure: %d", rc);

	rc = dfu_target_suit_write(manifest, manifest_len);
	zassert_equal(rc, 0, "Unexpected failure: %d", rc);

	rc = dfu_target_suit_offset_get(&offset);
	zassert_equal(rc, 0, "DFU target offset get should pass for image 0 %d", rc);
	zassert_equal(offset, manifest_len, "DFU target offset should be equal to image size");

	rc = dfu_target_done(true);
	zassert_equal(rc, 0, "Unexpected failure: %d", rc);

	rc = dfu_target_init(DFU_TARGET_IMAGE_TYPE_SUIT, TEST_IMAGE_CACHE_1_NUM,
			     dfu_cache_partition_len, NULL);
	zassert_equal(rc, 0, "Unexpected failure: %d", rc);

	rc = dfu_target_suit_write(dfu_cache_partition, dfu_cache_partition_len);
	zassert_equal(rc, 0, "Unexpected failure: %d", rc);

	rc = dfu_target_suit_offset_get(&offset);
	zassert_equal(rc, 0, "Unexpected failure: %d", rc);
	zassert_equal(offset, dfu_cache_partition_len,
		      "DFU target offset should be equal to image size");

	rc = dfu_target_done(true);
	zassert_equal(rc, 0, "Unexpected failure: %d", rc);

	rc = dfu_target_init(DFU_TARGET_IMAGE_TYPE_SUIT, TEST_IMAGE_CACHE_2_NUM,
			     dfu_cache_partition_len, NULL);
	zassert_equal(rc, 0, "Unexpected failure: %d", rc);

	rc = dfu_target_suit_write(dfu_cache_partition, dfu_cache_partition_len);
	zassert_equal(rc, 0, "Unexpected failure: %d", rc);

	rc = dfu_target_suit_offset_get(&offset);
	zassert_equal(rc, 0, "Unexpected failure: %d", rc);
	zassert_equal(offset, dfu_cache_partition_len,
		      "DFU target offset should be equal to image size");

	rc = dfu_target_done(true);
	zassert_equal(rc, 0, "Unexpected failure: %d", rc);

	rc = dfu_target_init(DFU_TARGET_IMAGE_TYPE_SUIT, TEST_IMAGE_CACHE_3_NUM,
			     dfu_cache_partition_len, NULL);
	zassert_equal(rc, 0, "Unexpected failure: %d", rc);

	rc = dfu_target_suit_write(dfu_cache_partition, dfu_cache_partition_len);
	zassert_equal(rc, 0, "Unexpected failure: %d", rc);

	rc = dfu_target_suit_offset_get(&offset);
	zassert_equal(rc, 0, "Unexpected failure: %d", rc);
	zassert_equal(offset, dfu_cache_partition_len,
		      "DFU target offset should be equal to image size");

	rc = dfu_target_done(true);
	zassert_equal(rc, 0, "Unexpected failure: %d", rc);

	rc = dfu_target_suit_schedule_update(0);
	zassert_equal(rc, 0, "Unexpected failure: %d", rc);

	dfu_target_suit_reboot();
	zassert_equal(suit_trigger_update_fake.call_count, 1,
		      "Incorrect number of suit_dfu_update_start() calls");

	rc = memcmp((uint8_t *)DFU_PARTITION_ADDRESS, manifest, manifest_len);
	zassert_equal(rc, 0, "DFU partition content does not match the manifest %d", rc);

	rc = memcmp((uint8_t *)CACHE_PARTITION_ADDRESS(1), dfu_cache_partition,
		    dfu_cache_partition_len);
	zassert_equal(rc, 0, "DFU cache partition content does not match the file content %d", rc);

	rc = memcmp((uint8_t *)CACHE_PARTITION_ADDRESS(2), dfu_cache_partition,
		    dfu_cache_partition_len);
	zassert_equal(rc, 0, "DFU cache partition content does not match the file content %d", rc);

	rc = memcmp((uint8_t *)CACHE_PARTITION_ADDRESS(3), dfu_cache_partition,
		    dfu_cache_partition_len);
	zassert_equal(rc, 0, "DFU cache partition content does not match the file content %d", rc);

	rc = dfu_target_suit_reset();
	zassert_equal(rc, 0, "Unexpected failure: %d", rc);

	zassert_equal(is_partition_empty(DFU_PARTITION_ADDRESS, DFU_PARTITION_SIZE), true,
		      "Partition should be empty after calling dfu_target_reset");
	zassert_equal(is_partition_empty(CACHE_PARTITION_ADDRESS(1), CACHE_PARTITION_SIZE(1)), true,
		      "Partition should be empty after calling dfu_target_reset");
	zassert_equal(is_partition_empty(CACHE_PARTITION_ADDRESS(2), CACHE_PARTITION_SIZE(2)), true,
		      "Partition should be empty after calling dfu_target_reset");
	zassert_equal(is_partition_empty(CACHE_PARTITION_ADDRESS(3), CACHE_PARTITION_SIZE(3)), true,
		      "Partition should be empty after calling dfu_target_reset");
}

ZTEST_SUITE(dfu_target_suit, NULL, NULL, setup_test, NULL, NULL);

#endif /* CONFIG_TESTS_SUIT_DFU_TARGET_SUIT_CACHE_PROCESSING */
```

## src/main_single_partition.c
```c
/*
 * Copyright (c) 2024 Nordic Semiconductor ASA
 *
 * SPDX-License-Identifier: LicenseRef-Nordic-5-Clause
 */

#ifdef CONFIG_TESTS_SUIT_DFU_TARGET_SUIT_SINGLE_PARTITION

#include <dfu/dfu_target.h>
#include <dfu/dfu_target_suit.h>

#include "common.h"

/* The SUIT envelopes are defined inside the respective manfest_*.c files. */
extern uint8_t manifest_with_payload[];
extern const size_t manifest_with_payload_len;

#define TEST_IMAGE_SIZE		 1024
#define TEST_IMAGE_ENVELOPE_NUM	 0
#define TEST_WRONG_IMAGE_CACHE_0 1
#define TEST_WRONG_IMAGE_CACHE_1 2

#define DFU_PARTITION_LABEL   dfu_partition
#define DFU_PARTITION_OFFSET  FIXED_PARTITION_OFFSET(DFU_PARTITION_LABEL)
#define DFU_PARTITION_ADDRESS suit_plat_mem_nvm_ptr_get(DFU_PARTITION_OFFSET)
#define DFU_PARTITION_SIZE    FIXED_PARTITION_SIZE(DFU_PARTITION_LABEL)
#define DFU_PARTITION_DEVICE  FIXED_PARTITION_DEVICE(DFU_PARTITION_LABEL)

static uint8_t dfu_target_buffer[TEST_IMAGE_SIZE];

static void setup_test(void *f)
{
	(void)f;

	reset_fakes();
}

ZTEST(dfu_target_suit, test_image_init)
{
	int rc;

	rc = dfu_target_suit_reset();
	zassert_equal(rc, 0, "Unexpected failure: %d", rc);
	zassert_equal(is_partition_empty(DFU_PARTITION_ADDRESS, DFU_PARTITION_SIZE), true,
		      "Partition should be empty after calling dfu_target_reset");

	rc = dfu_target_init(DFU_TARGET_IMAGE_TYPE_SUIT, TEST_IMAGE_ENVELOPE_NUM, TEST_IMAGE_SIZE,
			     NULL);
	zassert_equal(rc, -ENODEV,
		      "dfu_target should fail because the buffer has not been initialized. %d", rc);

	rc = dfu_target_suit_set_buf(dfu_target_buffer, sizeof(dfu_target_buffer));
	zassert_equal(rc, 0, "dfu_target should initialize the data buffer %d", rc);

	rc = dfu_target_init(DFU_TARGET_IMAGE_TYPE_SUIT, TEST_IMAGE_ENVELOPE_NUM, TEST_IMAGE_SIZE,
			     NULL);
	zassert_equal(rc, 0, "Unexpected failure: %d", rc);

	rc = dfu_target_init(DFU_TARGET_IMAGE_TYPE_SUIT, TEST_WRONG_IMAGE_CACHE_0, TEST_IMAGE_SIZE,
			     NULL);
	zassert_equal(rc, -ENOTSUP,
		      "dfu_target should fail because CACHE PROCESSING is not enabled: %d", rc);

	rc = dfu_target_init(DFU_TARGET_IMAGE_TYPE_SUIT, TEST_WRONG_IMAGE_CACHE_1, TEST_IMAGE_SIZE,
			     NULL);
	zassert_equal(rc, -ENOTSUP,
		      "dfu_target should fail because CACHE PROCESSING is not enabled: %d", rc);
}

ZTEST(dfu_target_suit, test_upload)
{
	int rc;
	size_t offset = 0;

	rc = dfu_target_suit_reset();
	zassert_equal(rc, 0, "Unexpected failure: %d", rc);

	rc = dfu_target_suit_set_buf(dfu_target_buffer, sizeof(dfu_target_buffer));
	zassert_equal(rc, 0, "dfu_target should initialize the data buffer %d", rc);

	rc = dfu_target_init(DFU_TARGET_IMAGE_TYPE_SUIT, TEST_IMAGE_ENVELOPE_NUM,
			     TEST_IMAGE_SIZE * 1000, NULL);
	zassert_equal(rc, -EFBIG, "dfu_target should not allow too big files. %d", rc);

	rc = dfu_target_init(DFU_TARGET_IMAGE_TYPE_SUIT, TEST_IMAGE_ENVELOPE_NUM, TEST_IMAGE_SIZE,
			     NULL);
	zassert_equal(rc, 0, "Unexpected failure: %d", rc);

	rc = dfu_target_suit_write(manifest_with_payload, manifest_with_payload_len);
	zassert_equal(rc, 0, "Unexpected failure: %d", rc);

	rc = dfu_target_suit_offset_get(&offset);
	zassert_equal(rc, 0, "DFU target offset get should pass for image 0 %d", rc);
	zassert_equal(offset, manifest_with_payload_len,
		      "DFU target offset should be equal to image size");

	rc = dfu_target_done(true);
	zassert_equal(rc, 0, "Unexpected failure: %d", rc);

	rc = dfu_target_suit_schedule_update(0);
	zassert_equal(rc, 0, "Unexpected failure: %d", rc);

	dfu_target_suit_reboot();
	zassert_equal(suit_trigger_update_fake.call_count, 1,
		      "Incorrect number of suit_trigger_update() calls");

	rc = memcmp((uint8_t *)DFU_PARTITION_ADDRESS, manifest_with_payload,
		    manifest_with_payload_len);
	zassert_equal(rc, 0, "DFU partition content does not match the manifest %d", rc);

	rc = dfu_target_suit_reset();
	zassert_equal(rc, 0, "Unexpected failure: %d", rc);
	zassert_equal(is_partition_empty(DFU_PARTITION_ADDRESS, DFU_PARTITION_SIZE), true,
		      "Partition should be empty after calling dfu_target_reset");
}

ZTEST_SUITE(dfu_target_suit, NULL, NULL, setup_test, NULL, NULL);

#endif /* CONFIG_TESTS_SUIT_DFU_TARGET_SUIT_SINGLE_PARTITION */
```

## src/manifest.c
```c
/*
 * Copyright (c) 2024 Nordic Semiconductor ASA
 *
 * SPDX-License-Identifier: LicenseRef-Nordic-5-Clause
 */

#include <stdint.h>
#include <stddef.h>

uint8_t manifest[] = {
	0xD8, 0x6B, 0xA3, 0x02, 0x58, 0x7A, 0x82, 0x58, 0x24, 0x82, 0x2F, 0x58, 0x20, 0xAB, 0xE7,
	0x1D, 0x6F, 0x8D, 0x4A, 0xD9, 0x4F, 0x84, 0xBC, 0x0A, 0xFB, 0x29, 0x61, 0x72, 0x74, 0xE6,
	0xB4, 0xF6, 0xE9, 0x81, 0x1C, 0xA6, 0xB9, 0x1A, 0xF3, 0x22, 0x40, 0x47, 0x28, 0x30, 0x6F,
	0x58, 0x51, 0xD2, 0x84, 0x4A, 0xA2, 0x01, 0x26, 0x04, 0x45, 0x1A, 0x7F, 0xFF, 0xFF, 0xE0,
	0xA0, 0xF6, 0x58, 0x40, 0x41, 0xB2, 0xE4, 0xFD, 0xC8, 0xA9, 0x4C, 0x4F, 0x1B, 0x23, 0xC6,
	0x0B, 0xAB, 0x3D, 0x99, 0x56, 0x4D, 0x84, 0x4E, 0x69, 0x82, 0xB1, 0x60, 0x42, 0x63, 0x63,
	0xC8, 0x5E, 0xF4, 0x6C, 0x6D, 0xDC, 0x32, 0x6E, 0x08, 0xA3, 0x83, 0x7C, 0x4A, 0xDE, 0x1D,
	0x07, 0xCA, 0xAC, 0x3D, 0x3C, 0xCD, 0xE7, 0xA7, 0x9B, 0xB4, 0xD1, 0xCD, 0x3D, 0x1C, 0x8F,
	0xD3, 0x4D, 0xC6, 0x3B, 0x65, 0x07, 0xCB, 0xA2, 0x03, 0x58, 0xB6, 0xA7, 0x01, 0x01, 0x02,
	0x01, 0x03, 0x58, 0x70, 0xA2, 0x02, 0x81, 0x84, 0x44, 0x63, 0x4D, 0x45, 0x4D, 0x41, 0x02,
	0x45, 0x1A, 0x0E, 0x16, 0x00, 0x00, 0x45, 0x1A, 0x00, 0x02, 0x00, 0x00, 0x04, 0x58, 0x56,
	0x86, 0x14, 0xA4, 0x01, 0x50, 0x76, 0x17, 0xDA, 0xA5, 0x71, 0xFD, 0x5A, 0x85, 0x8F, 0x94,
	0xE2, 0x8D, 0x73, 0x5C, 0xE9, 0xF4, 0x02, 0x50, 0xBA, 0x6C, 0x70, 0x4B, 0x1F, 0xD9, 0x5F,
	0x78, 0x91, 0x35, 0xBF, 0x04, 0xD9, 0xA4, 0xED, 0x31, 0x03, 0x58, 0x24, 0x82, 0x2F, 0x58,
	0x20, 0x5F, 0xC3, 0x54, 0xBF, 0x8E, 0x8C, 0x50, 0xFB, 0x4F, 0xBC, 0x2C, 0xFA, 0xEB, 0x04,
	0x53, 0x41, 0xC9, 0x80, 0x6D, 0xEA, 0xBD, 0xCB, 0x41, 0x54, 0xFB, 0x79, 0xCC, 0xA4, 0xF0,
	0xC9, 0x8C, 0x12, 0x0E, 0x19, 0x01, 0x00, 0x01, 0x0F, 0x02, 0x0F, 0x07, 0x43, 0x82, 0x03,
	0x0F, 0x09, 0x43, 0x82, 0x17, 0x02, 0x11, 0x52, 0x86, 0x14, 0xA1, 0x15, 0x69, 0x23, 0x66,
	0x69, 0x6C, 0x65, 0x2E, 0x62, 0x69, 0x6E, 0x15, 0x02, 0x03, 0x0F, 0x05, 0x82, 0x4C, 0x6B,
	0x49, 0x4E, 0x53, 0x54, 0x4C, 0x44, 0x5F, 0x4D, 0x46, 0x53, 0x54, 0x50, 0x5B, 0x46, 0x9F,
	0xD1, 0x90, 0xEE, 0x53, 0x9C, 0xA3, 0x18, 0x68, 0x1B, 0x03, 0x69, 0x5E, 0x36, 0x69, 0x23,
	0x66, 0x69, 0x6C, 0x65, 0x2E, 0x62, 0x69, 0x6E, 0x59, 0x01, 0x00, 0xC7, 0x9C, 0xAB, 0x9D,
	0xE8, 0x33, 0x7F, 0x30, 0x14, 0xEB, 0xAC, 0x02, 0xAF, 0x26, 0x01, 0x5E, 0x80, 0x6D, 0x88,
	0xA1, 0xDB, 0x11, 0xA7, 0x31, 0xDF, 0xA6, 0xEC, 0xCB, 0x9B, 0x48, 0x0D, 0xC8, 0x34, 0x40,
	0x6D, 0x30, 0x86, 0x7D, 0xE8, 0x1B, 0xEC, 0x3C, 0xF5, 0x40, 0xD0, 0x48, 0x18, 0x82, 0x11,
	0x9D, 0x7C, 0x3F, 0x6C, 0xE5, 0x8F, 0xF1, 0xD3, 0x5D, 0xE1, 0x51, 0xF7, 0x6A, 0x0F, 0xAF,
	0x0B, 0xBD, 0x4C, 0x5F, 0xA5, 0x34, 0x1A, 0x66, 0xDB, 0x22, 0xEC, 0x63, 0xED, 0x4B, 0xAB,
	0xC7, 0xC8, 0xF7, 0x59, 0xD8, 0xD6, 0x9E, 0xEC, 0x71, 0x1B, 0x24, 0x20, 0xB9, 0xAE, 0xE1,
	0x3B, 0xFC, 0xAE, 0xB8, 0x77, 0xAC, 0xA4, 0x57, 0x34, 0x97, 0x84, 0x4F, 0x58, 0xD5, 0x68,
	0x08, 0x6F, 0xE3, 0x9C, 0x7E, 0x1B, 0xD7, 0x38, 0x22, 0x98, 0x48, 0xF8, 0x7A, 0x67, 0xB2,
	0xD9, 0xAC, 0xC5, 0x34, 0xC1, 0x27, 0x82, 0x8E, 0x42, 0x79, 0x84, 0x21, 0x37, 0x4C, 0x41,
	0x4A, 0x0F, 0xE2, 0x7F, 0xA0, 0x6A, 0x19, 0x13, 0x3D, 0x52, 0x22, 0x7F, 0xD6, 0x2F, 0x71,
	0x12, 0x76, 0xAB, 0x25, 0x9C, 0xFC, 0x67, 0x08, 0x03, 0x7C, 0xDB, 0x18, 0xE6, 0x45, 0xF8,
	0x99, 0xC2, 0x9E, 0x2C, 0xE3, 0x9B, 0x25, 0xA9, 0x7B, 0x09, 0xFF, 0x00, 0x57, 0x26, 0x08,
	0x0A, 0x11, 0x42, 0xCF, 0x82, 0xA2, 0x6B, 0x2A, 0x99, 0xF9, 0x71, 0x9D, 0x14, 0x19, 0x5C,
	0x5C, 0x78, 0x31, 0x60, 0x42, 0x4A, 0x18, 0x1F, 0xEC, 0x78, 0x6A, 0x9A, 0x7C, 0x4F, 0xCF,
	0xE8, 0x5A, 0x29, 0x65, 0xCD, 0x01, 0x3B, 0x6D, 0x53, 0xBB, 0xC6, 0xDB, 0xDA, 0xD5, 0x8F,
	0xF7, 0xF4, 0xD9, 0xB9, 0x0A, 0x03, 0x4B, 0xFF, 0x33, 0xAB, 0x3B, 0xC5, 0xAF, 0xD0, 0xB8,
	0x2C, 0x0F, 0x6A, 0xA9, 0x11, 0xB0, 0xE8, 0x57, 0x8C, 0x92, 0x53, 0x81};

const size_t manifest_len = sizeof(manifest);
```
